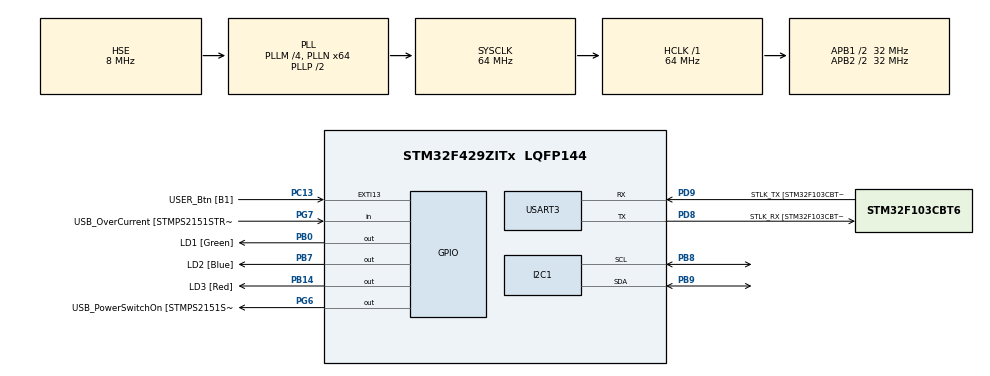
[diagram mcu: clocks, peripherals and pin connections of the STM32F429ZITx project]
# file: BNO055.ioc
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Mcu.Family=STM32F4
NVIC.USART3_IRQn=true\:0\:0\:false\:false\:true\:true\:true
RCC.CortexFreq_Value=64000000
PG6.Signal=GPIO_Output
Dma.USART3_TX.3.PeriphDataAlignment=DMA_PDATAALIGN_BYTE
Dma.I2C1_TX.1.Mode=DMA_NORMAL
Dma.USART3_TX.3.MemInc=DMA_MINC_ENABLE
PB14.GPIO_Label=LD3 [Red]
PA14.GPIO_Label=TCK
PG6.GPIO_Label=USB_PowerSwitchOn [STMPS2151STR_EN]
RCC.SYSCLKSourceVirtual=RCC_SYSCLKSOURCE_PLLCLK
PB0.GPIO_Label=LD1 [Green]
PC14/OSC32_IN.Mode=LSE-External-Oscillator
Dma.USART3_TX.3.MemDataAlignment=DMA_MDATAALIGN_BYTE
PC13.GPIO_Label=USER_Btn [B1]
PD9.Mode=Asynchronous
RCC.SYSCLKSource=RCC_SYSCLKSOURCE_PLLCLK
ProjectManager.StackSize=0x400
Dma.I2C1_TX.1.Direction=DMA_MEMORY_TO_PERIPH
Dma.USART3_RX.2.Priority=DMA_PRIORITY_HIGH
PH0/OSC_IN.Mode=HSE-External-Clock-Source
Dma.USART3_RX.2.PeriphInc=DMA_PINC_DISABLE
RCC.HCLKFreq_Value=64000000
RCC.APB2TimFreq_Value=64000000
Dma.I2C1_RX.0.PeriphDataAlignment=DMA_PDATAALIGN_BYTE
PH1/OSC_OUT.Signal=RCC_OSC_OUT
Dma.I2C1_TX.1.PeriphInc=DMA_PINC_DISABLE
PD8.Signal=USART3_TX
RCC.AHBFreq_Value=64000000
Dma.I2C1_RX.0.Priority=DMA_PRIORITY_LOW
RCC.HSE_VALUE=8000000
Dma.I2C1_RX.0.Mode=DMA_NORMAL
RCC.PLLMUL=RCC_PLL_MUL9
Dma.USART3_TX.3.Direction=DMA_MEMORY_TO_PERIPH
PA14.Mode=Serial_Wire
PB7.Signal=GPIO_Output
Dma.I2C1_RX.0.Direction=DMA_PERIPH_TO_MEMORY
PH1/OSC_OUT.Mode=HSE-External-Clock-Source
PB7.GPIO_Label=LD2 [Blue]
Mcu.Package=LQFP144
PB9.Signal=I2C1_SDA
PC14/OSC32_IN.Signal=RCC_OSC32_IN
RCC.APB2CLKDivider=RCC_HCLK_DIV2
Dma.Request2=USART3_RX
Dma.Request1=I2C1_TX
RCC.APB1TimFreq_Value=64000000
Dma.Request3=USART3_TX
NVIC.DMA1_Stream0_IRQn=true\:0\:0\:false\:false\:true\:false\:true
NVIC.DMA1_Stream6_IRQn=true\:0\:0\:false\:false\:true\:false\:true
Dma.Request0=I2C1_RX
Dma.I2C1_TX.1.PeriphDataAlignment=DMA_PDATAALIGN_BYTE
RCC.PLLSourceVirtual=RCC_PLLSOURCE_HSE
Dma.I2C1_RX.0.PeriphInc=DMA_PINC_DISABLE
Dma.I2C1_RX.0.MemDataAlignment=DMA_MDATAALIGN_BYTE
PG7.Signal=GPIO_Input
PD9.GPIO_Label=STLK_TX [STM32F103CBT6_PA2]
Dma.USART3_RX.2.Mode=DMA_NORMAL
PC13.Signal=GPXTI13
PD9.Signal=USART3_RX
NVIC.DMA1_Stream1_IRQn=true\:0\:0\:false\:false\:true\:false\:true
RCC.APB1CLKDivider=RCC_HCLK_DIV2
Dma.USART3_TX.3.PeriphInc=DMA_PINC_DISABLE
PD8.GPIO_Label=STLK_RX [STM32F103CBT6_PA3]
PA13.Signal=SYS_JTMS-SWDIO
Dma.USART3_RX.2.PeriphDataAlignment=DMA_PDATAALIGN_BYTE
Dma.USART3_RX.2.MemInc=DMA_MINC_ENABLE
ProjectManager.TargetToolchain=STM32CubeIDE
PB9.Mode=I2C
Dma.I2C1_RX.0.MemInc=DMA_MINC_ENABLE
Dma.I2C1_TX.1.Instance=DMA1_Stream6
Dma.USART3_TX.3.FIFOMode=DMA_FIFOMODE_DISABLE
RCC.USBFreq_Value=48000000
Dma.USART3_RX.2.Direction=DMA_PERIPH_TO_MEMORY
PD8.Mode=Asynchronous
PB14.Signal=GPIO_Output
Dma.USART3_TX.3.Instance=DMA1_Stream3
board=NUCLEO-F429ZI
RCC.VCOOutputFreq_Value=128000000
Dma.I2C1_TX.1.Priority=DMA_PRIORITY_LOW
Dma.I2C1_TX.1.FIFOMode=DMA_FIFOMODE_DISABLE
PH0/OSC_IN.Signal=RCC_OSC_IN
RCC.APB2Freq_Value=32000000
RCC.PRESCALERUSB=RCC_USBCLKSOURCE_PLL_DIV1_5
PG7.GPIO_Label=USB_OverCurrent [STMPS2151STR_FAULT]
Dma.I2C1_TX.1.MemInc=DMA_MINC_ENABLE
Dma.I2C1_TX.1.MemDataAlignment=DMA_MDATAALIGN_BYTE
PA13.Mode=Serial_Wire
Mcu.Name=STM32F429ZITx
PA13.GPIO_Label=TMS
Dma.USART3_TX.3.Mode=DMA_NORMAL
RCC.48MHZClocksFreq_Value=18285714.285714287
RCC.SYSCLKFreq_VALUE=64000000
USART3.VirtualMode=VM_ASYNC
PC15/OSC32_OUT.Mode=LSE-External-Oscillator
PA14.Signal=SYS_JTCK-SWCLK
ProjectManager.HeapSize=0x200
Dma.I2C1_RX.0.FIFOMode=DMA_FIFOMODE_DISABLE
Dma.USART3_RX.2.FIFOMode=DMA_FIFOMODE_DISABLE
RCC.HSI_VALUE=16000000
PH0/OSC_IN.GPIO_Label=MCO [STM32F103CBT6_PA8]
RCC.PLLQ=7
Dma.USART3_RX.2.MemDataAlignment=DMA_MDATAALIGN_BYTE
NVIC.PriorityGroup=NVIC_PRIORITYGROUP_4
RCC.PLLM=4
PB8.Mode=I2C
RCC.PLLN=64
PB8.Signal=I2C1_SCL
NVIC.DMA1_Stream3_IRQn=true\:0\:0\:false\:false\:true\:false\:true
PC15/OSC32_OUT.Signal=RCC_OSC32_OUT
Dma.USART3_RX.2.Instance=DMA1_Stream1
RCC.APB1Freq_Value=32000000
PB0.Signal=GPIO_Output
Dma.I2C1_RX.0.Instance=DMA1_Stream0
Dma.USART3_TX.3.Priority=DMA_PRIORITY_HIGH

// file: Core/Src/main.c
/* USER CODE BEGIN Header */
/**
  ******************************************************************************
  * @file           : main.c
  * @brief          : Main program body
  ******************************************************************************
  * @attention
  *
  * <h2><center>&copy; Copyright (c) 2021 STMicroelectronics.
  * All rights reserved.</center></h2>
  *
  * This software component is licensed by ST under BSD 3-Clause license,
  * the "License"; You may not use this file except in compliance with the
  * License. You may obtain a copy of the License at:
  *                        opensource.org/licenses/BSD-3-Clause
  *
  ******************************************************************************
  */
/* USER CODE END Header */
#include "main.h"

/* USER CODE BEGIN Includes */
#include <BNO055.h>
#include <roshandler.h>
/* USER CODE END Includes */

I2C_HandleTypeDef hi2c1;
DMA_HandleTypeDef hdma_i2c1_rx;
DMA_HandleTypeDef hdma_i2c1_tx;

UART_HandleTypeDef huart3;
DMA_HandleTypeDef hdma_usart3_rx;
DMA_HandleTypeDef hdma_usart3_tx;

void SystemClock_Config(void);
static void MX_GPIO_Init(void);
static void MX_DMA_Init(void);
static void MX_USART3_UART_Init(void);
static void MX_I2C1_Init(void);

int main(void)
{

  /* MCU Configuration--------------------------------------------------------*/

  /* Reset of all peripherals, Initializes the Flash interface and the Systick. */
  HAL_Init();

  /* Configure the system clock */
  SystemClock_Config();

  /* Initialize all configured peripherals */
  MX_GPIO_Init();
  MX_DMA_Init();
  MX_USART3_UART_Init();
  MX_I2C1_Init();
  /* USER CODE BEGIN 2 */
  BNO055_Init_I2C(&hi2c1);
  setup();
  /* USER CODE END 2 */

  /* Infinite loop */
  while (1)
  {
	  getIMU(&hi2c1, IMU_Euler, IMU_Quarternion);
	  loop();
  }
}

void SystemClock_Config(void)
{
  RCC_OscInitTypeDef RCC_OscInitStruct = {0};
  RCC_ClkInitTypeDef RCC_ClkInitStruct = {0};

  /** Configure the main internal regulator output voltage
  */
  __HAL_RCC_PWR_CLK_ENABLE();
  __HAL_PWR_VOLTAGESCALING_CONFIG(PWR_REGULATOR_VOLTAGE_SCALE3);
  /** Initializes the RCC Oscillators according to the specified parameters
  * in the RCC_OscInitTypeDef structure.
  */
  RCC_OscInitStruct.OscillatorType = RCC_OSCILLATORTYPE_HSE;
  RCC_OscInitStruct.HSEState = RCC_HSE_BYPASS;
  RCC_OscInitStruct.PLL.PLLState = RCC_PLL_ON;
  RCC_OscInitStruct.PLL.PLLSource = RCC_PLLSOURCE_HSE;
  RCC_OscInitStruct.PLL.PLLM = 4;
  RCC_OscInitStruct.PLL.PLLN = 64;
  RCC_OscInitStruct.PLL.PLLP = RCC_PLLP_DIV2;
  RCC_OscInitStruct.PLL.PLLQ = 7;
  if (HAL_RCC_OscConfig(&RCC_OscInitStruct) != HAL_OK)
  {
    Error_Handler();
  }
  /** Initializes the CPU, AHB and APB buses clocks
  */
  RCC_ClkInitStruct.ClockType = RCC_CLOCKTYPE_HCLK|RCC_CLOCKTYPE_SYSCLK
                              |RCC_CLOCKTYPE_PCLK1|RCC_CLOCKTYPE_PCLK2;
  RCC_ClkInitStruct.SYSCLKSource = RCC_SYSCLKSOURCE_PLLCLK;
  RCC_ClkInitStruct.AHBCLKDivider = RCC_SYSCLK_DIV1;
  RCC_ClkInitStruct.APB1CLKDivider = RCC_HCLK_DIV2;
  RCC_ClkInitStruct.APB2CLKDivider = RCC_HCLK_DIV2;

  if (HAL_RCC_ClockConfig(&RCC_ClkInitStruct, FLASH_LATENCY_2) != HAL_OK)
  {
    Error_Handler();
  }
}

static void MX_I2C1_Init(void)
{

  hi2c1.Instance = I2C1;
  hi2c1.Init.ClockSpeed = 100000;
  hi2c1.Init.DutyCycle = I2C_DUTYCYCLE_2;
  hi2c1.Init.OwnAddress1 = 0;
  hi2c1.Init.AddressingMode = I2C_ADDRESSINGMODE_7BIT;
  hi2c1.Init.DualAddressMode = I2C_DUALADDRESS_DISABLE;
  hi2c1.Init.OwnAddress2 = 0;
  hi2c1.Init.GeneralCallMode = I2C_GENERALCALL_DISABLE;
  hi2c1.Init.NoStretchMode = I2C_NOSTRETCH_DISABLE;
  if (HAL_I2C_Init(&hi2c1) != HAL_OK)
  {
    Error_Handler();
  }
  /** Configure Analogue filter
  */
  if (HAL_I2CEx_ConfigAnalogFilter(&hi2c1, I2C_ANALOGFILTER_ENABLE) != HAL_OK)
  {
    Error_Handler();
  }
  /** Configure Digital filter
  */
  if (HAL_I2CEx_ConfigDigitalFilter(&hi2c1, 0) != HAL_OK)
  {
    Error_Handler();
  }

}

static void MX_USART3_UART_Init(void)
{

  huart3.Instance = USART3;
  huart3.Init.BaudRate = 115200;
  huart3.Init.WordLength = UART_WORDLENGTH_8B;
  huart3.Init.StopBits = UART_STOPBITS_1;
  huart3.Init.Parity = UART_PARITY_NONE;
  huart3.Init.Mode = UART_MODE_TX_RX;
  huart3.Init.HwFlowCtl = UART_HWCONTROL_NONE;
  huart3.Init.OverSampling = UART_OVERSAMPLING_16;
  if (HAL_UART_Init(&huart3) != HAL_OK)
  {
    Error_Handler();
  }

}

static void MX_DMA_Init(void)
{

  /* DMA controller clock enable */
  __HAL_RCC_DMA1_CLK_ENABLE();

  /* DMA interrupt init */
  /* DMA1_Stream0_IRQn interrupt configuration */
  HAL_NVIC_SetPriority(DMA1_Stream0_IRQn, 0, 0);
  HAL_NVIC_EnableIRQ(DMA1_Stream0_IRQn);
  /* DMA1_Stream1_IRQn interrupt configuration */
  HAL_NVIC_SetPriority(DMA1_Stream1_IRQn, 0, 0);
  HAL_NVIC_EnableIRQ(DMA1_Stream1_IRQn);
  /* DMA1_Stream3_IRQn interrupt configuration */
  HAL_NVIC_SetPriority(DMA1_Stream3_IRQn, 0, 0);
  HAL_NVIC_EnableIRQ(DMA1_Stream3_IRQn);
  /* DMA1_Stream6_IRQn interrupt configuration */
  HAL_NVIC_SetPriority(DMA1_Stream6_IRQn, 0, 0);
  HAL_NVIC_EnableIRQ(DMA1_Stream6_IRQn);

}

static void MX_GPIO_Init(void)
{
  GPIO_InitTypeDef GPIO_InitStruct = {0};

  /* GPIO Ports Clock Enable */
  __HAL_RCC_GPIOC_CLK_ENABLE();
  __HAL_RCC_GPIOH_CLK_ENABLE();
  __HAL_RCC_GPIOB_CLK_ENABLE();
  __HAL_RCC_GPIOD_CLK_ENABLE();
  __HAL_RCC_GPIOG_CLK_ENABLE();
  __HAL_RCC_GPIOA_CLK_ENABLE();

  /*Configure GPIO pin Output Level */
  HAL_GPIO_WritePin(GPIOB, LD1_Pin|LD3_Pin|LD2_Pin, GPIO_PIN_RESET);

  /*Configure GPIO pin Output Level */
  HAL_GPIO_WritePin(USB_PowerSwitchOn_GPIO_Port, USB_PowerSwitchOn_Pin, GPIO_PIN_RESET);

  /*Configure GPIO pin : USER_Btn_Pin */
  GPIO_InitStruct.Pin = USER_Btn_Pin;
  GPIO_InitStruct.Mode = GPIO_MODE_IT_RISING;
  GPIO_InitStruct.Pull = GPIO_NOPULL;
  HAL_GPIO_Init(USER_Btn_GPIO_Port, &GPIO_InitStruct);

  /*Configure GPIO pins : LD1_Pin LD3_Pin LD2_Pin */
  GPIO_InitStruct.Pin = LD1_Pin|LD3_Pin|LD2_Pin;
  GPIO_InitStruct.Mode = GPIO_MODE_OUTPUT_PP;
  GPIO_InitStruct.Pull = GPIO_NOPULL;
  GPIO_InitStruct.Speed = GPIO_SPEED_FREQ_LOW;
  HAL_GPIO_Init(GPIOB, &GPIO_InitStruct);

  /*Configure GPIO pin : USB_PowerSwitchOn_Pin */
  GPIO_InitStruct.Pin = USB_PowerSwitchOn_Pin;
  GPIO_InitStruct.Mode = GPIO_MODE_OUTPUT_PP;
  GPIO_InitStruct.Pull = GPIO_NOPULL;
  GPIO_InitStruct.Speed = GPIO_SPEED_FREQ_LOW;
  HAL_GPIO_Init(USB_PowerSwitchOn_GPIO_Port, &GPIO_InitStruct);

  /*Configure GPIO pin : USB_OverCurrent_Pin */
  GPIO_InitStruct.Pin = USB_OverCurrent_Pin;
  GPIO_InitStruct.Mode = GPIO_MODE_INPUT;
  GPIO_InitStruct.Pull = GPIO_NOPULL;
  HAL_GPIO_Init(USB_OverCurrent_GPIO_Port, &GPIO_InitStruct);

}

void Error_Handler(void)
{
  __disable_irq();
  while (1)
  {
  }
}

/************************ (C) COPYRIGHT STMicroelectronics *****END OF FILE****/
